# CY8C5888LTI_LP097 register map
File version: 0.1
CY8C58LP
Registers are 8-bit, read-write, no defined reset value unless marked. A register's access mark holds for its fields unless they carry their own. Offsets are from the block's base; lines under a group give offsets from that group; [hi:lo] are bit positions; {n}, {i} and the like mark numbered series; 'fields as' and 'values as' point back to an identical list; <NAME> marks a mode.

## Memory map
0x00000000 freqcounter
0x00000000 UART
0x00000000 Timer
0x00000000 muxSel
0x00000000 Comp
0x00000000 Counter
0x00000000 PWM

## freqcounter
Base 0x00000000
0x40006404 freqcounter_COUNTER 32-bit — UDB.A0 - Current Counter Value
0x40006424 freqcounter_PERIOD 32-bit — UDB.D0 - Assigned Period
0x40006434 freqcounter_COMPARE 32-bit — UDB.D1 - Assigned Compare Value
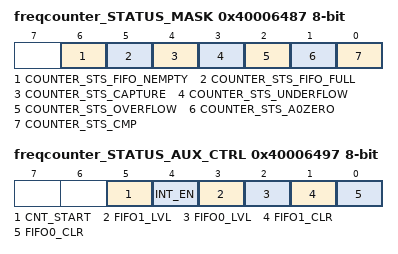
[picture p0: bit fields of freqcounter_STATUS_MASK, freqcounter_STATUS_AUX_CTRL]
0x40006487 freqcounter_STATUS_MASK — UDB Status bits Interrupt Mask Enable Register
  [6] COUNTER_STS_FIFO_NEMPTY — FIFO Not Empty Status
  [5] COUNTER_STS_FIFO_FULL — FIFO Full Status
  [4] COUNTER_STS_CAPTURE — Capture Status
  [3] COUNTER_STS_UNDERFLOW — Underflow status
  [2] COUNTER_STS_OVERFLOW — Overflow status
  [1] COUNTER_STS_A0ZERO — A0 Zero ouput status
  [0] COUNTER_STS_CMP — Compare output status
0x40006497 freqcounter_STATUS_AUX_CTRL — UDB Auxilliary Control Register
  [5] CNT_START — FIFO0 clear
    0=E_CNT_START0 (Disable counter); 1=E_CNT_START1 (Enable counter)
  [4] INT_EN
    0=E_INT_EN0 (Interrupt disabled); 1=E_INT_EN1 (Interrupt enabled)
  [3] FIFO1_LVL — FIFO level
    0=E_FIFO_LVL_0 (FIFO LVL: input mode: FIFO not full; output mode: FIFO not empty); 1=E_FIFO_LVL_1 (FIFO LVL: input mode: FIFO at least 1/2 empty; output mode: FIFO at least 1/2 full)
  [2] FIFO0_LVL — FIFO level
    values as FIFO1_LVL
  [1] FIFO1_CLR — FIFO1 clear
    0=E_FIFO_CLR_0 (Normal FIFO operation); 1=E_FIFO_CLR_1 (Clear FIFO state)
  [0] FIFO0_CLR — FIFO0 clear
    values as FIFO1_CLR

## UART
Base 0x00000000
0x4000652A RX_UART_RX_ADDRESS1 — RX Address1 Register
0x4000653A RX_UART_RX_ADDRESS2 — RX Address2 Register
0x40006548 TX_UART_TX_DATA — TX Data Register
0x4000654A RX_UART_RX_DATA — RX Data Register
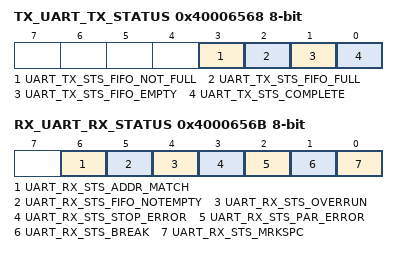
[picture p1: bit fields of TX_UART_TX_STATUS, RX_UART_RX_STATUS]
0x40006568 TX_UART_TX_STATUS — TX status register
  [3] UART_TX_STS_FIFO_NOT_FULL ro, [2] UART_TX_STS_FIFO_FULL ro, [1] UART_TX_STS_FIFO_EMPTY ro, [0] UART_TX_STS_COMPLETE ro
0x4000656B RX_UART_RX_STATUS — RX status register
  [6] UART_RX_STS_ADDR_MATCH ro, [5] UART_RX_STS_FIFO_NOTEMPTY ro, [4] UART_RX_STS_OVERRUN ro, [3] UART_RX_STS_STOP_ERROR ro, [2] UART_RX_STS_PAR_ERROR ro, [1] UART_RX_STS_BREAK ro, [0] UART_RX_STS_MRKSPC ro

## Timer
Base 0x00000000
0x4000640C Timer_COUNTER 32-bit — UDB.A0 - Current Down Counter Value
0x4000642C Timer_PERIOD 32-bit — UDB.D0 - Assigned Period
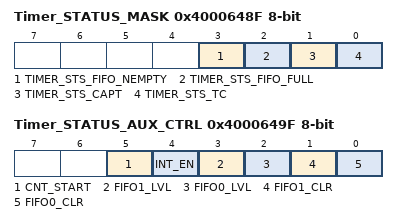
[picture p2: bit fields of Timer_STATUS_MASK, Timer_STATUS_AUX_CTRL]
0x4000648F Timer_STATUS_MASK — UDB Status bits Interrupt Mask Enable Register
  [3] TIMER_STS_FIFO_NEMPTY ro — FIFO Empty status
  [2] TIMER_STS_FIFO_FULL ro — FIFO Full Status
  [1] TIMER_STS_CAPT ro — Enables the Interrupt on Capture
  [0] TIMER_STS_TC ro — Enables the Interrupt on TC
0x4000649F Timer_STATUS_AUX_CTRL — UDB Auxilliary Control Register
  [5] CNT_START — FIFO0 clear
    0=E_CNT_START0 (Disable counter); 1=E_CNT_START1 (Enable counter)
  [4] INT_EN
    0=E_INT_EN0 (Interrupt disabled); 1=E_INT_EN1 (Interrupt enabled)
  [3] FIFO1_LVL — FIFO level
    0=E_FIFO_LVL_0 (FIFO LVL: input mode: FIFO not full; output mode: FIFO not empty); 1=E_FIFO_LVL_1 (FIFO LVL: input mode: FIFO at least 1/2 empty; output mode: FIFO at least 1/2 full)
  [2] FIFO0_LVL — FIFO level
    values as FIFO1_LVL
  [1] FIFO1_CLR — FIFO1 clear
    0=E_FIFO_CLR_0 (Normal FIFO operation); 1=E_FIFO_CLR_1 (Clear FIFO state)
  [0] FIFO0_CLR — FIFO0 clear
    values as FIFO1_CLR

## muxSel
Base 0x00000000
0x40006474 muxSel_CONTROL_REG

## Counter
Base 0x00000000
0x40006402 Counter_COUNTER 16-bit — UDB.A0 - Current Counter Value
0x40006422 Counter_PERIOD 16-bit — UDB.D0 - Assigned Period
0x40006432 Counter_COMPARE 16-bit — UDB.D1 - Assigned Compare Value
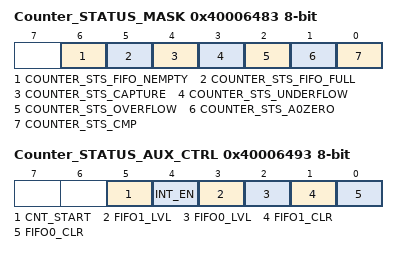
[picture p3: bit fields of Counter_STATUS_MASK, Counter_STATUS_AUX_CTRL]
0x40006483 Counter_STATUS_MASK — UDB Status bits Interrupt Mask Enable Register
  [6] COUNTER_STS_FIFO_NEMPTY — FIFO Not Empty Status
  [5] COUNTER_STS_FIFO_FULL — FIFO Full Status
  [4] COUNTER_STS_CAPTURE — Capture Status
  [3] COUNTER_STS_UNDERFLOW — Underflow status
  [2] COUNTER_STS_OVERFLOW — Overflow status
  [1] COUNTER_STS_A0ZERO — A0 Zero ouput status
  [0] COUNTER_STS_CMP — Compare output status
0x40006493 Counter_STATUS_AUX_CTRL — UDB Auxilliary Control Register
  [5] CNT_START — FIFO0 clear
    0=E_CNT_START0 (Disable counter); 1=E_CNT_START1 (Enable counter)
  [4] INT_EN
    0=E_INT_EN0 (Interrupt disabled); 1=E_INT_EN1 (Interrupt enabled)
  [3] FIFO1_LVL — FIFO level
    0=E_FIFO_LVL_0 (FIFO LVL: input mode: FIFO not full; output mode: FIFO not empty); 1=E_FIFO_LVL_1 (FIFO LVL: input mode: FIFO at least 1/2 empty; output mode: FIFO at least 1/2 full)
  [2] FIFO0_LVL — FIFO level
    values as FIFO1_LVL
  [1] FIFO1_CLR — FIFO1 clear
    0=E_FIFO_CLR_0 (Normal FIFO operation); 1=E_FIFO_CLR_1 (Clear FIFO state)
  [0] FIFO0_CLR — FIFO0 clear
    values as FIFO1_CLR
